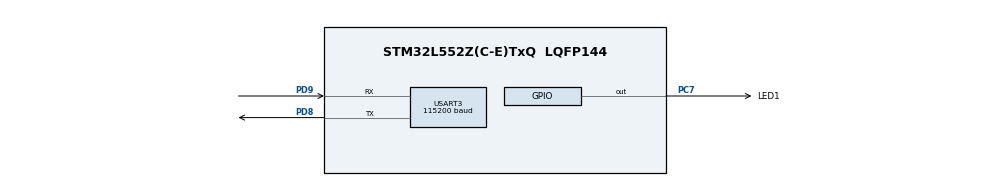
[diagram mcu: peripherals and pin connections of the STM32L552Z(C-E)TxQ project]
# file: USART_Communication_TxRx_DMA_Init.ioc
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Dma.Request0=USART3_TX
Dma.Request1=USART3_RX
Dma.USART3_RX.1.Channel_PRIV_NPRIV=DMA_CHANNEL_NPRIV_DISABLE
Dma.USART3_RX.1.Direction=DMA_PERIPH_TO_MEMORY
Dma.USART3_RX.1.EventEnable=DISABLE
Dma.USART3_RX.1.Instance=DMA1_Channel2
Dma.USART3_RX.1.MemDataAlignment=DMA_MDATAALIGN_BYTE
Dma.USART3_RX.1.MemInc=DMA_MINC_ENABLE
Dma.USART3_RX.1.Mode=DMA_NORMAL
Dma.USART3_RX.1.PeriphDataAlignment=DMA_PDATAALIGN_BYTE
Dma.USART3_RX.1.PeriphInc=DMA_PINC_DISABLE
Dma.USART3_RX.1.Polarity=HAL_DMAMUX_REQ_GEN_RISING
Dma.USART3_RX.1.Priority=DMA_PRIORITY_HIGH
Dma.USART3_RX.1.RequestNumber=1
Dma.USART3_RX.1.SignalID=NONE
Dma.USART3_RX.1.SyncEnable=DISABLE
Dma.USART3_RX.1.SyncPolarity=HAL_DMAMUX_SYNC_NO_EVENT
Dma.USART3_RX.1.SyncRequestNumber=1
Dma.USART3_RX.1.SyncSignalID=NONE
Dma.USART3_TX.0.Channel_PRIV_NPRIV=DMA_CHANNEL_NPRIV_DISABLE
Dma.USART3_TX.0.Direction=DMA_MEMORY_TO_PERIPH
Dma.USART3_TX.0.EventEnable=DISABLE
Dma.USART3_TX.0.Instance=DMA1_Channel1
Dma.USART3_TX.0.MemDataAlignment=DMA_MDATAALIGN_BYTE
Dma.USART3_TX.0.MemInc=DMA_MINC_ENABLE
Dma.USART3_TX.0.Mode=DMA_NORMAL
Dma.USART3_TX.0.PeriphDataAlignment=DMA_PDATAALIGN_BYTE
Dma.USART3_TX.0.PeriphInc=DMA_PINC_DISABLE
Dma.USART3_TX.0.Polarity=HAL_DMAMUX_REQ_GEN_RISING
Dma.USART3_TX.0.Priority=DMA_PRIORITY_HIGH
Dma.USART3_TX.0.RequestNumber=1
Dma.USART3_TX.0.SignalID=NONE
Dma.USART3_TX.0.SyncEnable=DISABLE
Dma.USART3_TX.0.SyncPolarity=HAL_DMAMUX_SYNC_NO_EVENT
Dma.USART3_TX.0.SyncRequestNumber=1
Dma.USART3_TX.0.SyncSignalID=NONE
Mcu.Family=STM32L5
Mcu.Name=STM32L552Z(C-E)TxQ
Mcu.Package=LQFP144
Mcu.TrustZone=disable
NVIC.DMA1_Channel1_IRQn=true\:0\:0\:false\:false\:true\:false\:true\:true
NVIC.DMA1_Channel2_IRQn=true\:0\:0\:false\:false\:true\:false\:true\:true
NVIC.PriorityGroup=NVIC_PRIORITYGROUP_3
NVIC.USART3_IRQn=true\:0\:0\:false\:false\:true\:true\:true\:true
PC7.GPIO_Label=LED1
PC7.GPIO_PuPd=GPIO_NOPULL
PC7.Signal=GPIO_Output
PD8.GPIO_PuPd=GPIO_PULLUP
PD8.GPIO_Speed=GPIO_SPEED_FREQ_HIGH
PD8.Mode=Asynchronous
PD8.Signal=USART3_TX
PD9.GPIO_PuPd=GPIO_PULLUP
PD9.GPIO_Speed=GPIO_SPEED_FREQ_HIGH
PD9.Mode=Asynchronous
PD9.Signal=USART3_RX
ProjectManager.HeapSize=0x200
ProjectManager.StackSize=0x400
ProjectManager.TargetToolchain=EWARM V8.32
RCC.ADCCLockSelection=RCC_ADCCLKSOURCE_SYSCLK
RCC.ADCFreq_Value=110000000
RCC.AHBFreq_Value=110000000
RCC.APB1Freq_Value=110000000
RCC.APB1TimFreq_Value=110000000
RCC.APB2Freq_Value=110000000
RCC.APB2TimFreq_Value=110000000
RCC.CortexFreq_Value=110000000
RCC.HCLKFreq_Value=110000000
RCC.HSE_VALUE=16000000
RCC.HSI48_VALUE=48000000
RCC.HSI_VALUE=16000000
RCC.LSE_VALUE=32768
RCC.MSI_VALUE=4000000
RCC.PLLN=55
RCC.PLLSAI1N=24
RCC.RTCClockSelection=RCC_RTCCLKSOURCE_LSE
RCC.SYSCLKFreq_VALUE=110000000
RCC.SYSCLKSource=RCC_SYSCLKSOURCE_PLLCLK
RCC.USBFreq_Value=48000000
RCC.VCOOutputFreq_Value=220000000
USART3.AutoBaudRateEnableParam=UART_ADVFEATURE_AUTOBAUDRATE_DISABLE
USART3.BaudRate=115200
USART3.ClockPrescaler=PRESCALER_DIV1
USART3.DMADisableonRxErrorParam=ADVFEATURE_DMA_ENABLEONRXERROR
USART3.DataInvertParam=ADVFEATURE_DATAINV_DISABLE
USART3.FIFOMode=FIFOMODE_DISABLE
USART3.MSBFirstParam=ADVFEATURE_MSBFIRST_DISABLE
USART3.Mode=MODE_TX_RX
USART3.OneBitSampling=UART_ONE_BIT_SAMPLE_DISABLE
USART3.OverSampling=UART_OVERSAMPLING_16
USART3.OverrunDisableParam=ADVFEATURE_OVERRUN_ENABLE
USART3.Parity=PARITY_NONE
USART3.RXFIFOThreshold=RXFIFO_THRESHOLD_1EIGHTHFULL
USART3.RxPinLevelInvertParam=ADVFEATURE_RXINV_DISABLE
USART3.StopBits=STOPBITS_1
USART3.SwapParam=ADVFEATURE_SWAP_DISABLE
USART3.TXFIFOThreshold=TXFIFO_THRESHOLD_1EIGHTHFULL
USART3.TxPinLevelInvertParam=ADVFEATURE_TXINV_DISABLE
USART3.VirtualMode-Asynchronous=VM_ASYNC
USART3.WordLength=WORDLENGTH_8B
VP_ICACHE_VS_ICACHE.Mode=DirectMappedCache
VP_PWR_VS_DBSignals.Mode=DisableDeadBatterySignals
board=custom

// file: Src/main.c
/* USER CODE BEGIN Header */
/**
  ******************************************************************************
  * @file    Examples_LL/USART/USART_Communication_TxRx_DMA_Init/Src/main.c
  * @author  MCD Application Team
  * @brief   This example describes how to send/receive bytes over USART IP using
  *          the STM32L5xx USART LL API in DMA mode.
  *          Peripheral initialization done using LL unitary services functions.
  ******************************************************************************
  * @attention
  *
  * Copyright (c) 2019 STMicroelectronics.
  * All rights reserved.
  *
  * This software is licensed under terms that can be found in the LICENSE file
  * in the root directory of this software component.
  * If no LICENSE file comes with this software, it is provided AS-IS.
  *
  ******************************************************************************
  */
/* USER CODE END Header */
#include "main.h"

/* USER CODE BEGIN PV */

__IO uint8_t ubButtonPress = 0;
__IO uint8_t ubSend = 0;
/* Buffer used for transmission */
const uint8_t aTxBuffer[] = "STM32L5xx USART LL API Example : TX/RX in DMA mode\r\nConfiguration UART 115200 bps, 8 data bit/1 stop bit/No parity/No HW flow control\r\nPlease enter 'END' string ...\r\n";
uint8_t ubNbDataToTransmit = sizeof(aTxBuffer);
__IO uint8_t ubTransmissionComplete = 0;

/* Buffer used for reception */
const uint8_t aStringToReceive[] = "END";
uint8_t ubNbDataToReceive = sizeof(aStringToReceive) - 1;
uint8_t aRxBuffer[sizeof(aStringToReceive) - 1];
__IO uint8_t ubReceptionComplete = 0;

/* USER CODE END PV */

void SystemClock_Config(void);
static void MX_GPIO_Init(void);
static void MX_DMA_Init(void);
static void MX_ICACHE_Init(void);
static void MX_USART3_UART_Init(void);
/* USER CODE BEGIN PFP */

void     StartTransfers(void);
void     LED_On(void);
void     LED_Blinking(uint32_t Period);
void     LED_Off(void);
void     UserButton_Init(void);
void     WaitForUserButtonPress(void);
void     WaitAndCheckEndOfTransfer(void);
uint8_t  Buffercmp8(uint8_t *pBuffer1, uint8_t *pBuffer2, uint8_t BufferLength);

/* USER CODE END PFP */

int main(void)
{

  /* MCU Configuration--------------------------------------------------------*/

  /* Reset of all peripherals, Initializes the Flash interface and the Systick. */
  LL_APB2_GRP1_EnableClock(LL_APB2_GRP1_PERIPH_SYSCFG);
  LL_APB1_GRP1_EnableClock(LL_APB1_GRP1_PERIPH_PWR);

  /* System interrupt init*/
  NVIC_SetPriorityGrouping(NVIC_PRIORITYGROUP_3);

  /** Disable the internal Pull-Up in Dead Battery pins of UCPD peripheral
  */
  LL_PWR_DisableUCPDDeadBattery();

  /* Configure the system clock */
  SystemClock_Config();

  /* USER CODE BEGIN SysInit */
  /* Initialize User push-button in EXTI mode */
  UserButton_Init();
  /* USER CODE END SysInit */

  /* Initialize all configured peripherals */
  MX_GPIO_Init();
  MX_DMA_Init();
  MX_ICACHE_Init();
  MX_USART3_UART_Init();
  /* USER CODE BEGIN 2 */
  /* Wait for User push-button press to start transfer */
  WaitForUserButtonPress();

  /* Initiate DMA transfers */
  StartTransfers();

  /* Wait for the end of the transfer and check received data */
  WaitAndCheckEndOfTransfer();

  /* USER CODE END 2 */

  /* Infinite loop */
  while (1)
  {

  }
}

void SystemClock_Config(void)
{
  LL_FLASH_SetLatency(LL_FLASH_LATENCY_5);
  while(LL_FLASH_GetLatency()!= LL_FLASH_LATENCY_5)
  {
  }

  LL_PWR_SetRegulVoltageScaling(LL_PWR_REGU_VOLTAGE_SCALE0);
  LL_RCC_MSI_Enable();

   /* Wait till MSI is ready */
  while(LL_RCC_MSI_IsReady() != 1)
  {
  }

  LL_RCC_MSI_EnableRangeSelection();
  LL_RCC_MSI_SetRange(LL_RCC_MSIRANGE_6);
  LL_RCC_MSI_SetCalibTrimming(0);
  LL_RCC_PLL_ConfigDomain_SYS(LL_RCC_PLLSOURCE_MSI, LL_RCC_PLLM_DIV_1, 55, LL_RCC_PLLR_DIV_2);
  LL_RCC_PLL_EnableDomain_SYS();
  LL_RCC_PLL_Enable();

   /* Wait till PLL is ready */
  while(LL_RCC_PLL_IsReady() != 1)
  {
  }

   /* Intermediate AHB prescaler 2 when target frequency clock is higher than 80 MHz */
   LL_RCC_SetAHBPrescaler(LL_RCC_SYSCLK_DIV_2);

  LL_RCC_SetSysClkSource(LL_RCC_SYS_CLKSOURCE_PLL);

   /* Wait till System clock is ready */
  while(LL_RCC_GetSysClkSource() != LL_RCC_SYS_CLKSOURCE_STATUS_PLL)
  {
  }

  /* Insure 1us transition state at intermediate medium speed clock*/
  for (__IO uint32_t i = (RCC_MAX_FREQUENCY_MHZ >> 1); i !=0; i--);

  LL_RCC_SetAHBPrescaler(LL_RCC_SYSCLK_DIV_1);
  LL_RCC_SetAPB1Prescaler(LL_RCC_APB1_DIV_1);
  LL_RCC_SetAPB2Prescaler(LL_RCC_APB2_DIV_1);

  LL_Init1msTick(110000000);

  LL_SetSystemCoreClock(110000000);
}

static void MX_ICACHE_Init(void)
{

  /** Enable instruction cache in 1-way (direct mapped cache)
  */
  LL_ICACHE_SetMode(LL_ICACHE_1WAY);
  LL_ICACHE_Enable();

}

static void MX_USART3_UART_Init(void)
{

  LL_USART_InitTypeDef USART_InitStruct = {0};

  LL_GPIO_InitTypeDef GPIO_InitStruct = {0};

  LL_RCC_SetUSARTClockSource(LL_RCC_USART3_CLKSOURCE_PCLK1);

  /* Peripheral clock enable */
  LL_APB1_GRP1_EnableClock(LL_APB1_GRP1_PERIPH_USART3);

  LL_AHB2_GRP1_EnableClock(LL_AHB2_GRP1_PERIPH_GPIOD);
  /**USART3 GPIO Configuration
  PD8   ------> USART3_TX
  PD9   ------> USART3_RX
  */
  GPIO_InitStruct.Pin = LL_GPIO_PIN_8|LL_GPIO_PIN_9;
  GPIO_InitStruct.Mode = LL_GPIO_MODE_ALTERNATE;
  GPIO_InitStruct.Speed = LL_GPIO_SPEED_FREQ_HIGH;
  GPIO_InitStruct.OutputType = LL_GPIO_OUTPUT_PUSHPULL;
  GPIO_InitStruct.Pull = LL_GPIO_PULL_UP;
  GPIO_InitStruct.Alternate = LL_GPIO_AF_7;
  LL_GPIO_Init(GPIOD, &GPIO_InitStruct);

  /* USART3 DMA Init */

  /* USART3_TX Init */
  LL_DMA_SetPeriphRequest(DMA1, LL_DMA_CHANNEL_1, LL_DMAMUX_REQ_USART3_TX);

  LL_DMA_SetDataTransferDirection(DMA1, LL_DMA_CHANNEL_1, LL_DMA_DIRECTION_MEMORY_TO_PERIPH);

  LL_DMA_SetChannelPriorityLevel(DMA1, LL_DMA_CHANNEL_1, LL_DMA_PRIORITY_HIGH);

  LL_DMA_SetMode(DMA1, LL_DMA_CHANNEL_1, LL_DMA_MODE_NORMAL);

  LL_DMA_SetPeriphIncMode(DMA1, LL_DMA_CHANNEL_1, LL_DMA_PERIPH_NOINCREMENT);

  LL_DMA_SetMemoryIncMode(DMA1, LL_DMA_CHANNEL_1, LL_DMA_MEMORY_INCREMENT);

  LL_DMA_SetPeriphSize(DMA1, LL_DMA_CHANNEL_1, LL_DMA_PDATAALIGN_BYTE);

  LL_DMA_SetMemorySize(DMA1, LL_DMA_CHANNEL_1, LL_DMA_MDATAALIGN_BYTE);

  LL_DMA_DisableChannelPrivilege(DMA1, LL_DMA_CHANNEL_1);

  /* USART3_RX Init */
  LL_DMA_SetPeriphRequest(DMA1, LL_DMA_CHANNEL_2, LL_DMAMUX_REQ_USART3_RX);

  LL_DMA_SetDataTransferDirection(DMA1, LL_DMA_CHANNEL_2, LL_DMA_DIRECTION_PERIPH_TO_MEMORY);

  LL_DMA_SetChannelPriorityLevel(DMA1, LL_DMA_CHANNEL_2, LL_DMA_PRIORITY_HIGH);

  LL_DMA_SetMode(DMA1, LL_DMA_CHANNEL_2, LL_DMA_MODE_NORMAL);

  LL_DMA_SetPeriphIncMode(DMA1, LL_DMA_CHANNEL_2, LL_DMA_PERIPH_NOINCREMENT);

  LL_DMA_SetMemoryIncMode(DMA1, LL_DMA_CHANNEL_2, LL_DMA_MEMORY_INCREMENT);

  LL_DMA_SetPeriphSize(DMA1, LL_DMA_CHANNEL_2, LL_DMA_PDATAALIGN_BYTE);

  LL_DMA_SetMemorySize(DMA1, LL_DMA_CHANNEL_2, LL_DMA_MDATAALIGN_BYTE);

  LL_DMA_DisableChannelPrivilege(DMA1, LL_DMA_CHANNEL_2);

  /* USART3 interrupt Init */
  NVIC_SetPriority(USART3_IRQn, NVIC_EncodePriority(NVIC_GetPriorityGrouping(),0, 0));
  NVIC_EnableIRQ(USART3_IRQn);

  /* USER CODE BEGIN USART3_Init 1 */
  /* Configure the DMA functional parameters for transmission */
  LL_DMA_ConfigAddresses(DMA1, LL_DMA_CHANNEL_1,
                         (uint32_t)aTxBuffer,
                         LL_USART_DMA_GetRegAddr(USART3, LL_USART_DMA_REG_DATA_TRANSMIT),
                         LL_DMA_GetDataTransferDirection(DMA1, LL_DMA_CHANNEL_1));
  LL_DMA_SetDataLength(DMA1, LL_DMA_CHANNEL_1, ubNbDataToTransmit);

  /* Configure the DMA functional parameters for reception */
  LL_DMA_ConfigAddresses(DMA1, LL_DMA_CHANNEL_2,
                         LL_USART_DMA_GetRegAddr(USART3, LL_USART_DMA_REG_DATA_RECEIVE),
                         (uint32_t)aRxBuffer,
                         LL_DMA_GetDataTransferDirection(DMA1, LL_DMA_CHANNEL_2));
  LL_DMA_SetDataLength(DMA1, LL_DMA_CHANNEL_2, ubNbDataToReceive);

  /* Enable DMA transfer complete/error interrupts  */
  LL_DMA_EnableIT_TC(DMA1, LL_DMA_CHANNEL_1);
  LL_DMA_EnableIT_TE(DMA1, LL_DMA_CHANNEL_1);
  LL_DMA_EnableIT_TC(DMA1, LL_DMA_CHANNEL_2);
  LL_DMA_EnableIT_TE(DMA1, LL_DMA_CHANNEL_2);
  /* USER CODE END USART3_Init 1 */
  USART_InitStruct.PrescalerValue = LL_USART_PRESCALER_DIV1;
  USART_InitStruct.BaudRate = 115200;
  USART_InitStruct.DataWidth = LL_USART_DATAWIDTH_8B;
  USART_InitStruct.StopBits = LL_USART_STOPBITS_1;
  USART_InitStruct.Parity = LL_USART_PARITY_NONE;
  USART_InitStruct.TransferDirection = LL_USART_DIRECTION_TX_RX;
  USART_InitStruct.HardwareFlowControl = LL_USART_HWCONTROL_NONE;
  USART_InitStruct.OverSampling = LL_USART_OVERSAMPLING_16;
  LL_USART_Init(USART3, &USART_InitStruct);
  LL_USART_SetTXFIFOThreshold(USART3, LL_USART_FIFOTHRESHOLD_1_8);
  LL_USART_SetRXFIFOThreshold(USART3, LL_USART_FIFOTHRESHOLD_1_8);
  LL_USART_DisableFIFO(USART3);
  LL_USART_ConfigAsyncMode(USART3);
  LL_USART_Enable(USART3);
  /* USER CODE BEGIN USART3_Init 2 */

  /* Polling USART initialisation */
  while ((!(LL_USART_IsActiveFlag_TEACK(USART3))) || (!(LL_USART_IsActiveFlag_REACK(USART3))))
  {
  }
  /* USER CODE END USART3_Init 2 */

}

static void MX_DMA_Init(void)
{

  /* Init with LL driver */
  /* DMA controller clock enable */
  LL_AHB1_GRP1_EnableClock(LL_AHB1_GRP1_PERIPH_DMAMUX1);
  LL_AHB1_GRP1_EnableClock(LL_AHB1_GRP1_PERIPH_DMA1);

  /* DMA interrupt init */
  /* DMA1_Channel1_IRQn interrupt configuration */
  NVIC_SetPriority(DMA1_Channel1_IRQn, NVIC_EncodePriority(NVIC_GetPriorityGrouping(),0, 0));
  NVIC_EnableIRQ(DMA1_Channel1_IRQn);
  /* DMA1_Channel2_IRQn interrupt configuration */
  NVIC_SetPriority(DMA1_Channel2_IRQn, NVIC_EncodePriority(NVIC_GetPriorityGrouping(),0, 0));
  NVIC_EnableIRQ(DMA1_Channel2_IRQn);

}

static void MX_GPIO_Init(void)
{
  LL_GPIO_InitTypeDef GPIO_InitStruct = {0};

  /* GPIO Ports Clock Enable */
  LL_AHB2_GRP1_EnableClock(LL_AHB2_GRP1_PERIPH_GPIOD);
  LL_AHB2_GRP1_EnableClock(LL_AHB2_GRP1_PERIPH_GPIOC);

  /**/
  LL_GPIO_ResetOutputPin(LED1_GPIO_Port, LED1_Pin);

  /**/
  GPIO_InitStruct.Pin = LED1_Pin;
  GPIO_InitStruct.Mode = LL_GPIO_MODE_OUTPUT;
  GPIO_InitStruct.Speed = LL_GPIO_SPEED_FREQ_LOW;
  GPIO_InitStruct.OutputType = LL_GPIO_OUTPUT_PUSHPULL;
  GPIO_InitStruct.Pull = LL_GPIO_PULL_NO;
  LL_GPIO_Init(LED1_GPIO_Port, &GPIO_InitStruct);

}

/* USER CODE BEGIN 4 */

/**
  * @brief  This function initiates TX and RX DMA transfers by enabling DMA channels
  * @param  None
  * @retval None
  */
void StartTransfers(void)
{
  /* Enable DMA RX Interrupt */
  LL_USART_EnableDMAReq_RX(USART3);

  /* Enable DMA TX Interrupt */
  LL_USART_EnableDMAReq_TX(USART3);

  /* Enable DMA Channel Rx */
  LL_DMA_EnableChannel(DMA1, LL_DMA_CHANNEL_2);

  /* Enable DMA Channel Tx */
  LL_DMA_EnableChannel(DMA1, LL_DMA_CHANNEL_1);
}

/**
  * @brief  Turn-on LED1.
  * @param  None
  * @retval None
  */
void LED_On(void)
{
  /* Turn LED1 on */
  LL_GPIO_SetOutputPin(LED1_GPIO_Port, LED1_Pin);
}

/**
  * @brief  Turn-off LED1.
  * @param  None
  * @retval None
  */
void LED_Off(void)
{
  /* Turn LED1 off */
  LL_GPIO_ResetOutputPin(LED1_GPIO_Port, LED1_Pin);
}

/**
  * @brief  Set LED1 to Blinking mode for an infinite loop (toggle period based on value provided as input parameter).
  * @param  Period : Period of time (in ms) between each toggling of LED
  *   This parameter can be user defined values. Pre-defined values used in that example are :
  *     @arg LED_BLINK_FAST : Fast Blinking
  *     @arg LED_BLINK_SLOW : Slow Blinking
  *     @arg LED_BLINK_ERROR : Error specific Blinking
  * @retval None
  */
void LED_Blinking(uint32_t Period)
{
  /* Toggle LED1 in an infinite loop */
  while (1)
  {
    LL_GPIO_TogglePin(LED1_GPIO_Port, LED1_Pin);
    LL_mDelay(Period);
  }
}

/**
  * @brief  Configures User push-button in GPIO or EXTI Line Mode.
  * @param  None
  * @retval None
  */
void UserButton_Init(void)
{
  /* Enable the BUTTON Clock */
  USER_BUTTON_GPIO_CLK_ENABLE();

  /* Configure GPIO for BUTTON */
  LL_GPIO_SetPinMode(USER_BUTTON_GPIO_PORT, USER_BUTTON_PIN, LL_GPIO_MODE_INPUT);
  LL_GPIO_SetPinPull(USER_BUTTON_GPIO_PORT, USER_BUTTON_PIN, LL_GPIO_PULL_NO);

  /* Connect External Line to the GPIO*/
  USER_BUTTON_SYSCFG_SET_EXTI();

  /* Enable a rising trigger External line 13 Interrupt */
  USER_BUTTON_EXTI_LINE_ENABLE();
  USER_BUTTON_EXTI_FALLING_TRIG_ENABLE();

  /* Configure NVIC for USER_BUTTON_EXTI_IRQn */
  NVIC_SetPriority(USER_BUTTON_EXTI_IRQn, 3);
  NVIC_EnableIRQ(USER_BUTTON_EXTI_IRQn);
}

/**
  * @brief  Wait for User push-button press to start transfer.
  * @param  None
  * @retval None
  */
/*  */
void WaitForUserButtonPress(void)
{
  while (ubButtonPress == 0)
  {
    LL_GPIO_TogglePin(LED1_GPIO_Port, LED1_Pin);
    LL_mDelay(LED_BLINK_FAST);
  }
  /* Ensure that LED1 is turned Off */
  LED_Off();
}

/**
  * @brief  Wait end of transfer and check if received Data are well.
  * @param  None
  * @retval None
  */
void WaitAndCheckEndOfTransfer(void)
{
  /* 1 - Wait end of transmission */
  while (ubTransmissionComplete != 1)
  {
  }
  /* Disable DMA1 Tx Channel */
  LL_DMA_DisableChannel(DMA1, LL_DMA_CHANNEL_1);

  /* 2 - Wait end of reception */
  while (ubReceptionComplete != 1)
  {
  }
  /* Disable DMA1 Rx Channel */
  LL_DMA_DisableChannel(DMA1, LL_DMA_CHANNEL_2);

  /* 3 - Compare received string to expected one */
  if (Buffercmp8((uint8_t *)aStringToReceive, (uint8_t *)aRxBuffer, ubNbDataToReceive))
  {
    /* Processing Error */
    LED_Blinking(LED_BLINK_ERROR);
  }
  else
  {
    /* Turn On Led if data are well received */
    LED_On();
  }
}

/**
* @brief Compares two 8-bit buffers and returns the comparison result.
* @param pBuffer1: pointer to the source buffer to be compared to.
* @param pBuffer2: pointer to the second source buffer to be compared to the first.
* @param BufferLength: buffer's length.
* @retval   0: Comparison is OK (the two Buffers are identical)
*           Value different from 0: Comparison is NOK (Buffers are different)
*/
uint8_t Buffercmp8(uint8_t *pBuffer1, uint8_t *pBuffer2, uint8_t BufferLength)
{
  while (BufferLength--)
  {
    if (*pBuffer1 != *pBuffer2)
    {
      return 1;
    }

    pBuffer1++;
    pBuffer2++;
  }

  return 0;
}

/******************************************************************************/
/*   USER IRQ HANDLER TREATMENT Functions                                     */
/******************************************************************************/
/**
  * @brief  Function to manage User push-button
  * @param  None
  * @retval None
  */
void UserButton_Callback(void)
{
  /* Update User push-button variable : to be checked in waiting loop in main program */
  ubButtonPress = 1;
}

/**
  * @brief  Function called from DMA1 IRQ Handler when Tx transfer is completed
  * @param  None
  * @retval None
  */
void DMA1_TransmitComplete_Callback(void)
{
  /* DMA Tx transfer completed */
  ubTransmissionComplete = 1;
}

/**
  * @brief  Function called from DMA1 IRQ Handler when Rx transfer is completed
  * @param  None
  * @retval None
  */
void DMA1_ReceiveComplete_Callback(void)
{
  /* DMA Rx transfer completed */
  ubReceptionComplete = 1;
}

/**
  * @brief  Function called in case of error detected in USART IT Handler
  * @param  None
  * @retval None
  */
void USART_TransferError_Callback(void)
{
  /* Disable DMA1 Tx Channel */
  LL_DMA_DisableChannel(DMA1, LL_DMA_CHANNEL_1);

  /* Disable DMA1 Rx Channel */
  LL_DMA_DisableChannel(DMA1, LL_DMA_CHANNEL_2);

  /* Set LED1 to Blinking mode to indicate error occurs */
  LED_Blinking(LED_BLINK_ERROR);
}

/* USER CODE END 4 */

void Error_Handler(void)
{
  while(1)
  {
  }
}

#ifdef  USE_FULL_ASSERT
/**
  * @brief  Reports the name of the source file and the source line number
  *         where the assert_param error has occurred.
  * @param  file: pointer to the source file name
  * @param  line: assert_param error line source number
  * @retval None
  */
void assert_failed(uint8_t *file, uint32_t line)
{
  /* USER CODE BEGIN 6 */
  /* User can add his own implementation to report the file name and line number,
     ex: printf("Wrong parameters value: file %s on line %d\r\n", file, line) */
  /* Infinite loop */
  while (1)
  {}
  /* USER CODE END 6 */
}
#endif /* USE_FULL_ASSERT */
